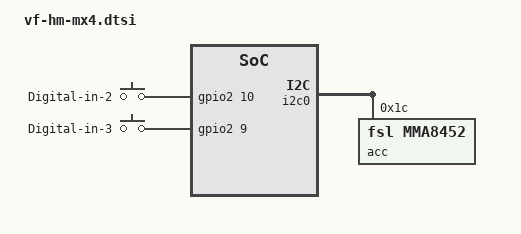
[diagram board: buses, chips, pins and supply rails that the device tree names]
#include <dt-bindings/input/input.h>
#include "vf610-pinfunc.h"

/* Digital in 2 and 3 are mapped as input keys and also configured as wakeup sources. 
 * Accelerometer does only have interrupt pin 1, only mapped to iomux so it can be exported. 
*/
/ {
    digital-io {
        compatible = "gpio-keys";
        pinctrl-names = "default";
        pinctrl-0 = <&pinctrl_digin>;

        digin2 {
            label = "Digital-in-2";
            gpios = <&gpio2 10 GPIO_ACTIVE_HIGH>;
            linux,code = <KEY_POWER>;
            debounce-interval = <10>;
            gpio-key,wakeup;
        };  

        digin3 {
            label = "Digital-in-3";
            gpios = <&gpio2 9 GPIO_ACTIVE_HIGH>;
            linux,code = <KEY_POWER>;
            debounce-interval = <10>;
            gpio-key,wakeup;
        };


    };
};

&iomuxc {
    vf610-colibri {
        pinctrl_digin: gpiokeys {
            fsl,pins = <
                VF610_PAD_PTB20__GPIO_42    0x219d
                VF610_PAD_PTB19__GPIO_41    0x219d
            >;
        };

        pinctrl_acc: gpio-acc {
            fsl,pins = <
                VF610_PAD_PTD31__GPIO_63    0x219d
            >;
        };

    };
};

&i2c0 {
    acc: mma8452q@1c {
        compatible = "fsl,mma8452";
        reg = <0x1c>;
    };
};
